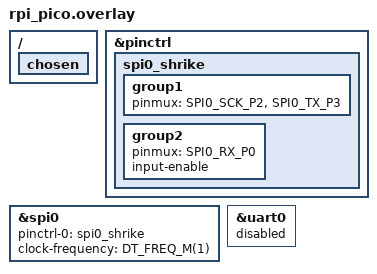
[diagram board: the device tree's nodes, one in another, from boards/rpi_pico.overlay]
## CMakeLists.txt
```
# SPDX-License-Identifier: Apache-2.0
# Shrike-Lite の C のデモ（RP2040、Zephyr）。FPGA の回路（FPGA_IMAGE = fpga_mcu.bin）を埋め込み、起動時に SPI で送る。
# ビルドは build.py --firmware から（ZephyrToolchain.build。-DFPGA_IMAGE=<fpga_mcu.bin の絶対パス>）。
cmake_minimum_required(VERSION 3.20.0)
find_package(Zephyr REQUIRED HINTS $ENV{ZEPHYR_BASE})
project(shrike_c_demo)

if(NOT DEFINED FPGA_IMAGE)
  message(FATAL_ERROR "FPGA_IMAGE（FPGA の回路 fpga_mcu.bin）を -DFPGA_IMAGE= で渡す")
endif()

target_sources(app PRIVATE src/main.c src/fpga_load.c src/accel.c src/scenario.c)
generate_inc_file_for_target(app ${FPGA_IMAGE} ${ZEPHYR_BINARY_DIR}/include/generated/fpga_image.inc)
```

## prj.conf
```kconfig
# SPI（FPGA の回路の送り込みと演算器のレジスタ）・GPIO（CS・FPGA の電源と有効・マーカー）
CONFIG_SPI=y
CONFIG_GPIO=y

# ログは RTT（fprobe が SWD で読む）。UART0 は GPIO0・1 が SPI と CS なので使わない
CONFIG_USE_SEGGER_RTT=y
CONFIG_CONSOLE=y
CONFIG_RTT_CONSOLE=y
CONFIG_UART_CONSOLE=n
CONFIG_SERIAL=n
CONFIG_PRINTK=y

# fprobe の RTOS の表示（host/fprobe/rtos/zephyr.py）
CONFIG_THREAD_MONITOR=y
CONFIG_THREAD_NAME=y
CONFIG_THREAD_STACK_INFO=y
CONFIG_INIT_STACKS=y
CONFIG_DEBUG_THREAD_INFO=y

# ソース行・変数で追いやすく
CONFIG_DEBUG_OPTIMIZATIONS=y
```

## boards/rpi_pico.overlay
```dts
/* Shrike-Lite: RP2040 と ForgeFPGA の間の SPI（GPIO0 = MISO、2 = SCK、3 = MOSI。CS = GPIO1 は GPIO で手で）。
 * GPIO0・1 は rpi_pico の既定では UART0 なので止める（ログは RTT）。GPIO12 = FPGA の電源、13 = 有効、
 * 26 = 要求中のマーカー、27 = 題材の印（どれも GPIO で手で）。 */
&pinctrl {
	spi0_shrike: spi0_shrike {
		group1 {
			pinmux = <SPI0_SCK_P2>, <SPI0_TX_P3>;
		};
		group2 {
			pinmux = <SPI0_RX_P0>;
			input-enable;
		};
	};
};

&spi0 {
	pinctrl-0 = <&spi0_shrike>;
	clock-frequency = <DT_FREQ_M(1)>;
};

&uart0 {
	status = "disabled";
};

/ {
	chosen {
		/delete-property/ zephyr,console;
		/delete-property/ zephyr,shell-uart;
	};
};
```

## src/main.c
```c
/* SPDX-License-Identifier: Apache-2.0
 * Shrike-Lite の C のデモ（MCU 側）: FPGA に回路を送り、演算器に A × B を頼んで結果を確かめ続ける。
 * 要求のスレッド req: A・B を書いて開始 → STATUS を g_poll_limit 回まで読む → 足りなければリトライ（待ち回数を倍に）
 * → RESULT を A × B と比べる。GPIO26 = 要求中 1（リトライのたびに一度 0 に戻す）。g_log_every 回ごとに RTT へ 1 行。 */
#include <zephyr/device.h>
#include <zephyr/drivers/gpio.h>
#include <zephyr/kernel.h>
#include <zephyr/sys/printk.h>

#include "accel.h"
#include "demo.h"
#include "fpga_load.h"
#include "scenario.h"

#define USED __attribute__((used))

USED volatile uint32_t g_requests;
USED volatile uint32_t g_errors;
USED volatile uint32_t g_retries;
USED volatile uint32_t g_last_a;
USED volatile uint32_t g_last_b;
USED volatile uint32_t g_last_result;
USED volatile uint32_t g_fpga_id;
USED volatile uint32_t g_scenario;
USED volatile uint32_t g_poll_limit = 16;
USED volatile uint32_t g_s2_rate = 10;
USED volatile uint32_t g_log_every = 100;
USED volatile uint32_t g_reset;
USED volatile uint32_t g_s3_period_us = 99991;

static const struct device *const gpio = DEVICE_DT_GET(DT_NODELABEL(gpio0));
static uint32_t seed = 12345;

static uint8_t rand8(void)
{
	seed = seed * 1103515245u + 12345u;
	return (seed >> 16) & 0xFF;
}

/* FPGA に回路を送って ID を確かめる。合わなければ false（要求しない） */
static bool start_fpga(void)
{
	scenario_quiesce();                         /* 題材の割り込みが送り込みの CS を乱さないように */
	int err = fpga_load(fpga_image, fpga_image_len);

	accel_init();
	g_fpga_id = accel_read(REG_ID);
	if (err || g_fpga_id != FPGA_ID) {
		printk("fpga: load error %d, id 0x%04x (expected 0x%04x)\n", err, g_fpga_id, FPGA_ID);
		return false;
	}
	printk("fpga: loaded %u bytes, id 0x%04x\n", (unsigned)fpga_image_len, g_fpga_id);
	return true;
}

#define POLLS_MAX (1u << 20)

/* 1 回の要求。結果を *result に入れて true。PC から題材の切り替え・送り直しを頼まれたら途中でやめて false
 * （S4 で FPGA が固まると、ここから抜けられなくなるため） */
static bool request(uint8_t a, uint8_t b, uint32_t scenario, uint16_t *result)
{
	uint32_t polls = g_poll_limit;

	gpio_pin_set(gpio, PIN_MARK, 1);
	accel_write(REG_A, a);
	accel_write(REG_B, b);
	accel_write(REG_CTRL, 1);
	for (;;) {
		uint32_t k;

		for (k = 0; k < polls; k++) {
			if (accel_read(REG_STATUS) & STATUS_DONE) {
				break;
			}
			/* 長い待ち（最大 2^20 回 ≒ 25 秒）の途中でも PC の切り替え・送り直しに応える */
			if ((k & 0xFFu) == 0xFFu && (g_reset || g_scenario != scenario)) {
				gpio_pin_set(gpio, PIN_MARK, 0);
				return false;
			}
		}
		if (k < polls) {
			break;
		}
		if (g_reset || g_scenario != scenario) {
			gpio_pin_set(gpio, PIN_MARK, 0);
			return false;
		}
		g_retries++;                  /* タイムアウト: リトライ（次は倍まで待つ） */
		if (scenario == 4) {
			scenario_cue();       /* S4: タイムアウトを検知した瞬間の印 */
		}
		if (polls < POLLS_MAX) {
			polls *= 2;
		}
		gpio_pin_set(gpio, PIN_MARK, 0);
		gpio_pin_set(gpio, PIN_MARK, 1);
		accel_write(REG_CTRL, 1);
	}
	*result = accel_read(REG_RESULT);
	gpio_pin_set(gpio, PIN_MARK, 0);
	return true;
}

static void req_main(void *p1, void *p2, void *p3)
{
	uint32_t applied = UINT32_MAX;

	gpio_pin_configure(gpio, PIN_MARK, GPIO_OUTPUT_LOW);
	gpio_pin_configure(gpio, PIN_CUE, GPIO_OUTPUT_LOW);
	bool loaded = start_fpga();

	seed ^= k_cycle_get_32();
	for (;;) {
		if (g_reset || !loaded) {                 /* PC から: FPGA を送り直す（固まりから戻す等） */
			while (!loaded && !g_reset) {     /* 送れなかった・ID が違う: 要求を止めて送り直しを待つ */
				k_msleep(100);
			}
			g_reset = 0;
			loaded = start_fpga();
			applied = UINT32_MAX;
			if (!loaded) {
				continue;
			}
		}
		if (g_scenario != applied) {
			applied = g_scenario;
			scenario_apply(applied);
		}
		uint8_t a = rand8(), b = rand8();
		uint16_t result;

		if (!request(a, b, applied, &result)) {
			continue;
		}
		bool ok = result == (uint16_t)(a * b);   /* 結果の比較（ソース行のブレークポイントの例） */

		g_requests++;
		if (!ok) {
			g_errors++;
		}
		g_last_a = a;
		g_last_b = b;
		g_last_result = result;
		uint32_t every = g_log_every;            /* PC が途中で 0 を書いても 0 で割らない */

		if (every && g_requests % every == 0) {
			printk("req %u a %u b %u result %u %s errors %u retries %u\n", g_requests, a, b, result,
			       ok ? "ok" : "NG", g_errors, g_retries);
		}
		k_msleep(5);
	}
}

K_THREAD_DEFINE(req, 2048, req_main, NULL, NULL, NULL, 5, 0, 0);
```

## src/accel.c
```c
/* SPDX-License-Identifier: Apache-2.0 */
#include <zephyr/device.h>
#include <zephyr/drivers/gpio.h>
#include <zephyr/drivers/spi.h>

#include "accel.h"
#include "demo.h"

static const struct device *const gpio = DEVICE_DT_GET(DT_NODELABEL(gpio0));
static const struct device *const spi = DEVICE_DT_GET(DT_NODELABEL(spi0));

static const struct spi_config cfg = {
	.frequency = 1000000,
	.operation = SPI_WORD_SET(8) | SPI_TRANSFER_MSB | SPI_OP_MODE_MASTER,
};

int accel_init(void)
{
	return gpio_pin_configure(gpio, PIN_SPI_CS, GPIO_OUTPUT_HIGH);
}

static void frame(const uint8_t tx[3], uint8_t rx[3])
{
	const struct spi_buf tb = {.buf = (void *)tx, .len = 3};
	const struct spi_buf rb = {.buf = rx, .len = 3};
	const struct spi_buf_set txs = {.buffers = &tb, .count = 1};
	const struct spi_buf_set rxs = {.buffers = &rb, .count = 1};

	gpio_pin_set(gpio, PIN_SPI_CS, 0);
	spi_transceive(spi, &cfg, &txs, &rxs);
	gpio_pin_set(gpio, PIN_SPI_CS, 1);
}

void accel_write(uint8_t addr, uint16_t v)
{
	const uint8_t tx[3] = {addr, v >> 8, v & 0xFF};
	uint8_t rx[3];

	frame(tx, rx);
}

uint16_t accel_read(uint8_t addr)
{
	const uint8_t tx[3] = {0x80 | addr, 0, 0};
	uint8_t rx[3] = {0, 0, 0};                      /* SPI が失敗しても初期化されないスタックの値を返さない */

	frame(tx, rx);
	return (uint16_t)(rx[1] << 8 | rx[2]);
}
```

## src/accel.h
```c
/* SPDX-License-Identifier: Apache-2.0
 * FPGA の演算器（rtl/demo_accel.vhd）のレジスタを SPI で読み書きする（3 バイトのフレーム: 書き = addr・上位・下位、
 * 読み = 0x80|addr・0・0 で返りの 2・3 バイト目）。 */
#ifndef ACCEL_H
#define ACCEL_H

#include <stdint.h>

enum accel_reg {
	REG_ID = 0x00, REG_CTRL = 0x01, REG_A = 0x02, REG_B = 0x03, REG_RESULT = 0x04,
	REG_STATUS = 0x06, REG_LEFT = 0x07, REG_MODE = 0x08, REG_S2_MASK = 0x09, REG_EVENTS = 0x0A,
};

#define STATUS_BUSY 0x1u
#define STATUS_DONE 0x2u

int accel_init(void);
void accel_write(uint8_t addr, uint16_t v);
uint16_t accel_read(uint8_t addr);

#endif
```

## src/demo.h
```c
/* SPDX-License-Identifier: Apache-2.0
 * Shrike-Lite の C のデモ: ピンと、fprobe が名前で読み書きする大域変数。 */
#ifndef DEMO_H
#define DEMO_H

#include <stdint.h>

/* RP2040 の GPIO */
#define PIN_SPI_CS   1    /* FPGA の SPI の CS（回路の送り込みと演算器で共通） */
#define PIN_FPGA_PWR 12
#define PIN_FPGA_EN  13
#define PIN_MARK     26   /* 要求中 1（ロジアナ ch 10） */
#define PIN_CUE      27   /* 題材の印（PMOD JB 7 = ロジアナ ch 14） */

#define FPGA_ID 0x5D01u

/* fprobe が名前で読む（g_scenario 等は書いて題材を切り替える）。volatile: 外から読み書きされる */
extern volatile uint32_t g_requests;
extern volatile uint32_t g_errors;
extern volatile uint32_t g_retries;
extern volatile uint32_t g_last_a;
extern volatile uint32_t g_last_b;
extern volatile uint32_t g_last_result;
extern volatile uint32_t g_fpga_id;
extern volatile uint32_t g_scenario;
extern volatile uint32_t g_poll_limit;
extern volatile uint32_t g_s2_rate;
extern volatile uint32_t g_log_every;
extern volatile uint32_t g_reset;
extern volatile uint32_t g_s3_period_us;

#endif
```

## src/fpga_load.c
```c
/* SPDX-License-Identifier: Apache-2.0
 * FPGA（ForgeFPGA SLG47910）に回路を送る。手順は Shrike の公式のライブラリ（vicharak-in/shrike_flash の
 * ShrikeFlash.cpp）と同じ: CS・EN・PWR を下げて 100 ms → EN・PWR を上げて 100 ms → 500 ms → CS を上げて 2 ms →
 * CS を下げる → SPI モード 0・MSB 先頭で回路のデータをそのまま送る → CS を上げて 100 ms。 */
#include <zephyr/device.h>
#include <zephyr/drivers/gpio.h>
#include <zephyr/drivers/spi.h>
#include <zephyr/kernel.h>

#include "demo.h"
#include "fpga_load.h"

const uint8_t fpga_image[] = {
#include "fpga_image.inc"
};
const size_t fpga_image_len = sizeof(fpga_image);

static const struct device *const gpio = DEVICE_DT_GET(DT_NODELABEL(gpio0));
static const struct device *const spi = DEVICE_DT_GET(DT_NODELABEL(spi0));

static const struct spi_config load_cfg = {
	.frequency = 1600000,   /* 公式のライブラリの既定 */
	.operation = SPI_WORD_SET(8) | SPI_TRANSFER_MSB | SPI_OP_MODE_MASTER,
};

int fpga_load(const uint8_t *image, size_t len)
{
	int err = gpio_pin_configure(gpio, PIN_SPI_CS, GPIO_OUTPUT_LOW) |
		  gpio_pin_configure(gpio, PIN_FPGA_EN, GPIO_OUTPUT_LOW) |
		  gpio_pin_configure(gpio, PIN_FPGA_PWR, GPIO_OUTPUT_LOW);
	if (err) {
		return -EIO;
	}
	k_msleep(100);
	gpio_pin_set(gpio, PIN_FPGA_EN, 1);
	gpio_pin_set(gpio, PIN_FPGA_PWR, 1);
	k_msleep(100);
	k_msleep(500);
	gpio_pin_set(gpio, PIN_SPI_CS, 1);
	k_usleep(2000);
	gpio_pin_set(gpio, PIN_SPI_CS, 0);

	const struct spi_buf buf = {.buf = (void *)image, .len = len};
	const struct spi_buf_set tx = {.buffers = &buf, .count = 1};
	err = spi_write(spi, &load_cfg, &tx);

	gpio_pin_set(gpio, PIN_SPI_CS, 1);
	k_msleep(100);
	return err;
}
```

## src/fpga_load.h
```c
/* SPDX-License-Identifier: Apache-2.0 */
#ifndef FPGA_LOAD_H
#define FPGA_LOAD_H

#include <stddef.h>
#include <stdint.h>

/* 埋め込んだ FPGA の回路（build.py が fpga_mcu.bin から作る） */
extern const uint8_t fpga_image[];
extern const size_t fpga_image_len;

/* Shrike の手順で FPGA に回路を送る（vicharak-in/shrike_flash と同じ）。0 = 成功、負 = SPI・GPIO の誤り。 */
int fpga_load(const uint8_t *image, size_t len);

#endif
```

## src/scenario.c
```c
/* SPDX-License-Identifier: Apache-2.0 */
#include <zephyr/device.h>
#include <zephyr/drivers/gpio.h>
#include <zephyr/kernel.h>

#include "accel.h"
#include "demo.h"
#include "scenario.h"

/* RP2040 の SIO（GPIO の出力を 1 命令で読み書きする）。S3 の割り込みが直接書く */
#define SIO_GPIO_OUT (*(volatile uint32_t *)0xD0000010u)

static const struct device *const gpio = DEVICE_DT_GET(DT_NODELABEL(gpio0));

/* S3: 割り込みの中で「題材の印を反転する」つもりの処理。出力の写し out_copy は、割り込みを始めたときの出力
 * （CS = 1・マーカー = 0 の空き時間）のまま更新しないので、転送の途中に当たると CS を 1 に戻してしまう
 * （GPIO の出力の読み・変更・書きの競合。SET/CLR の 1 ビットの書きを使えば起きない） */
static uint32_t out_copy;

static void s3_tick(struct k_timer *t)
{
	ARG_UNUSED(t);
	out_copy ^= BIT(PIN_CUE);
	SIO_GPIO_OUT = out_copy;
}

K_TIMER_DEFINE(s3_timer, s3_tick, NULL);

void scenario_quiesce(void)
{
	k_timer_stop(&s3_timer);
	gpio_pin_set(gpio, PIN_CUE, 0);
}

void scenario_apply(uint32_t s)
{
	static const uint16_t mode[] = {0, 0x1, 0x2, 0x0, 0x5};
	uint16_t m = s < ARRAY_SIZE(mode) ? mode[s] : 0;

	scenario_quiesce();
	accel_write(REG_S2_MASK, s == 2 ? g_s2_rate : 0);
	accel_write(REG_MODE, m);                     /* MODE を書くと S4 の固まりも解ける */
	g_poll_limit = s == 2 ? 128 : 16;             /* S2 はリトライさせない（取りこぼしだけを見る） */
	if (s == 3) {
		out_copy = SIO_GPIO_OUT;
		k_timer_start(&s3_timer, K_USEC(g_s3_period_us), K_USEC(g_s3_period_us));
	}
}

void scenario_cue(void)
{
	gpio_pin_set(gpio, PIN_CUE, 1);
	gpio_pin_set(gpio, PIN_CUE, 0);
}
```

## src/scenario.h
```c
/* SPDX-License-Identifier: Apache-2.0
 * 題材（g_scenario）: MCU と FPGA の連携の不具合を実行中に切り替える（仕様 §4）。
 *   0 = 不具合なし
 *   1 = S1（MCU → FPGA）: 待ち回数が短く、計算中にリトライが来ると FPGA が途中の和を消さない（MODE bit0）
 *   2 = S2（FPGA → MCU）: FPGA がまれに A・B の書き込みを取りこぼす（MODE bit1。頻度は g_s2_rate = LFSR のビット数）
 *   3 = S3（タイミング）: タイマ割り込みが GPIO の出力を古い写しで丸ごと書き戻す（題材の印 GPIO27 を反転するつもりで、
 *       転送中なら CS も上げてしまう）。周期は g_s3_period_us（既定 99991 µs = 約 10 回/秒）
 *   4 = S4（1 回きり）: S1 に加えて、A = 0xFF でリトライが来ると FPGA が固まる（MODE bit2）。g_scenario = 0 と
 *       g_reset = 1 で戻す。頻度は g_poll_limit（大きいほどリトライが減ってまれになる） */
#ifndef SCENARIO_H
#define SCENARIO_H

#include <stdint.h>

/* 題材 s を演算器と割り込みに反映する（g_poll_limit は題材の既定に設定し直す。その後は PC から変えてよい） */
void scenario_apply(uint32_t s);

/* 題材の割り込みを止める（FPGA に回路を送る前に必ず。S3 の割り込みは CS を含む GPIO の出力を書き戻すので、
 * 動いたまま送ると回路のデータが乱れて FPGA が電源の入れ直しまで戻らなかった。2026-10-21） */
void scenario_quiesce(void);

/* 題材の印（GPIO27）を 1 回パルスにする（S4: タイムアウトを検知した瞬間） */
void scenario_cue(void);

#endif
```
